# STM32H562xx register map
File version: 1.0
Registers are 32-bit, read-write, reset 0x0 unless marked. A register's access mark holds for its fields unless they carry their own. Offsets are from the block's base; [hi:lo] are bit positions; {n}, {i} and the like mark numbered series.

## VREFBUF
Base 0x44007400
Same registers: VREFBUF_S 0x54007400
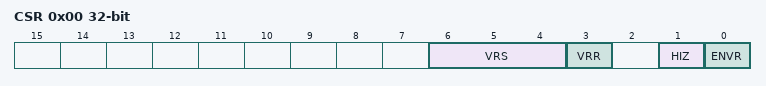
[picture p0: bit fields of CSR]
0x00 CSR — VREFBUF control and status register
  [6:4] VRS — Voltage reference scale
    {v}=SCALE{v} (Voltage reference scale {v} (VREF_OUT{v+1})) (v=0..3)
  [3] VRR — Voltage reference buffer ready
  [1] HIZ — High impedance mode
  [0] ENVR — Voltage reference buffer enable
0x04 CCR — VREFBUF calibration and control register
  [5:0] TRIM — TRIM[5:0] bits (Trimming code)

## PWR — Power Control
Base 0x44020800
Same registers: PWR_S 0x54020800
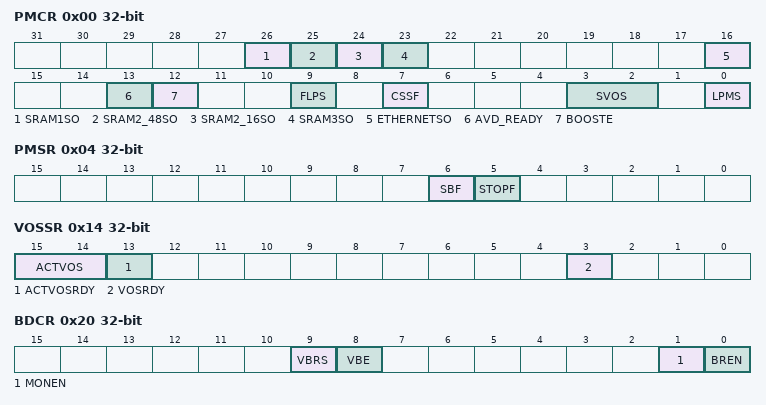
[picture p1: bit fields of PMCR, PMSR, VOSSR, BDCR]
0x00 PMCR — Power mode control register
  [26] SRAM1SO
  [25] SRAM2_48SO
  [24] SRAM2_16SO
  [23] SRAM3SO
  [16] ETHERNETSO
  [13] AVD_READY
  [12] BOOSTE
  [9] FLPS
  [7] CSSF
  [3:2] SVOS
    3=SCALE3 (Select voltage scale 3 when system enters STOP mode); 2=SCALE4 (Select voltage scale 4 when system enters STOP mode); 1=SCALE5 (Select voltage scale 5 when system enters STOP mode)
  [0] LPMS
    0=STOP_MODE (STOP 0 mode); 1=STANDBY_MODE
0x04 PMSR — Power mode status register
  [6] SBF, [5] STOPF
0x10 VOSCR — Voltage scaling control register
  [5:4] VOS
    3=SCALE0 (Voltage scaling range 0); 2=SCALE1 (Voltage scaling range 1); 1=SCALE2 (Voltage scaling range 2); 0=SCALE3 (Voltage scaling range 3)
0x14 VOSSR — Voltage sacling status register
  [15:14] ACTVOS, [13] ACTVOSRDY, [3] VOSRDY
0x20 BDCR — BacKup domain control register
  [9] VBRS
    0=RESISTOR_5K (Charge the battery through a 5 kO resistor); 1=RESISTOR_1_5K (Charge the battery through a 1.5 kO resistor)
  [8] VBE
  [1] MONEN
  [0] BREN
0x24 DBPCR — DBP control register
  [0] DBP
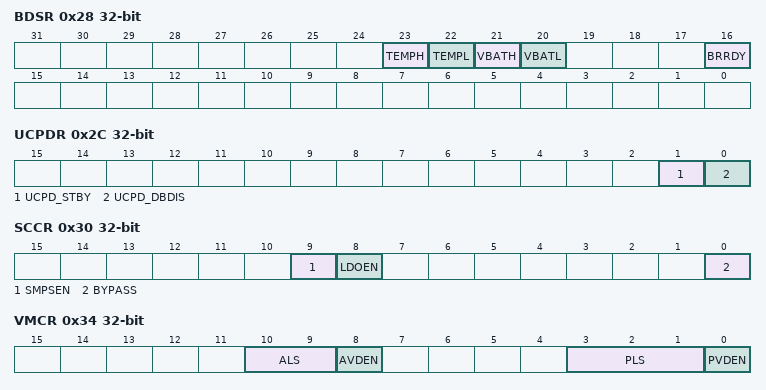
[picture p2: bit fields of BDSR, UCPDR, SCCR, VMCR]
0x28 BDSR — BacKup domain status register
  [23] TEMPH, [22] TEMPL, [21] VBATH, [20] VBATL, [16] BRRDY
0x2C UCPDR — Usb typeC and Power Delivery Register
  [1] UCPD_STBY, [0] UCPD_DBDIS
0x30 SCCR — Supply configuration control register
  [9] SMPSEN, [8] LDOEN, [0] BYPASS
0x34 VMCR — Voltage Monitor Control Register
  [10:9] ALS
    0=AVDLEVEL_0 (Analog Voltage threshold detected by AVD 1.7 V); 1=AVDLEVEL_1 (Analog Voltage threshold detected by AVD 2.1 V); 2=AVDLEVEL_2 (Analog Voltage threshold detected by AVD 2.5 V); 3=AVDLEVEL_3 (Analog Voltage threshold detected by AVD 2.8 V)
  [8] AVDEN
  [3:1] PLS
    0=PVDLEVEL_0 (Voltage threshold detected by PVD 1.95 V); 1=PVDLEVEL_1 (Voltage threshold detected by PVD 2.10 V); 2=PVDLEVEL_2 (Voltage threshold detected by PVD 2.25 V); 3=PVDLEVEL_3 (Voltage threshold detected by PVD 2.40 V); 4=PVDLEVEL_4 (Voltage threshold detected by PVD 2.55 V); 5=PVDLEVEL_5 (Voltage threshold detected by PVD 2.70 V); 6=PVDLEVEL_6 (Voltage threshold detected by PVD 2.85 V); 7=PVDLEVEL_7
  [0] PVDEN
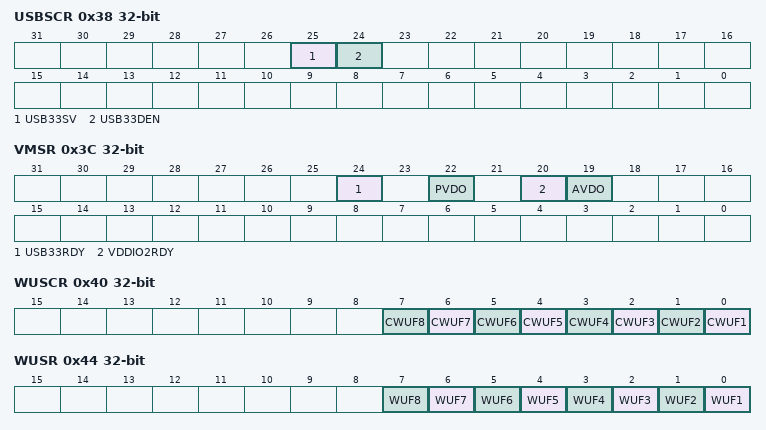
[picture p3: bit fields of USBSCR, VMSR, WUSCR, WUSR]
0x38 USBSCR — USB Supply Control Register
  [25] USB33SV, [24] USB33DEN
0x3C VMSR — Status Register Voltage Monitoring
  [24] USB33RDY, [22] PVDO, [20] VDDIO2RDY, [19] AVDO
0x40 WUSCR — WakeUP status clear register
  [n-1] CWUF{n} (n=1..8)
0x44 WUSR — WakeUP status Register
  [n-1] WUF{n} (n=1..8)
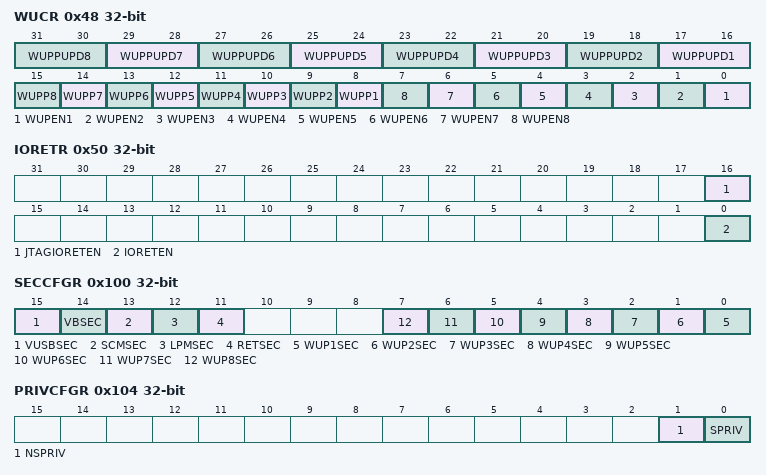
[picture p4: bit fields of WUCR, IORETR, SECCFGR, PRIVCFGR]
0x48 WUCR — WakeUP configuration register
  [2n+15:2n+14] WUPPUPD{n} (n=1..8), [n+7] WUPP{n} (n=1..8), [n-1] WUPEN{n} (n=1..8)
0x50 IORETR — IO RETention Register
  [16] JTAGIORETEN, [0] IORETEN
0x100 SECCFGR — Security configuration register
  [15] VUSBSEC, [14] VBSEC, [13] SCMSEC, [12] LPMSEC, [11] RETSEC, [n-1] WUP{n}SEC (n=1..8)
0x104 PRIVCFGR — Privilege configuration register
  [1] NSPRIV, [0] SPRIV

## EXTI — Asynch Interrupt/Event Controller (EXTI)
Base 0x44022000
Same registers: EXTI_S 0x54022000
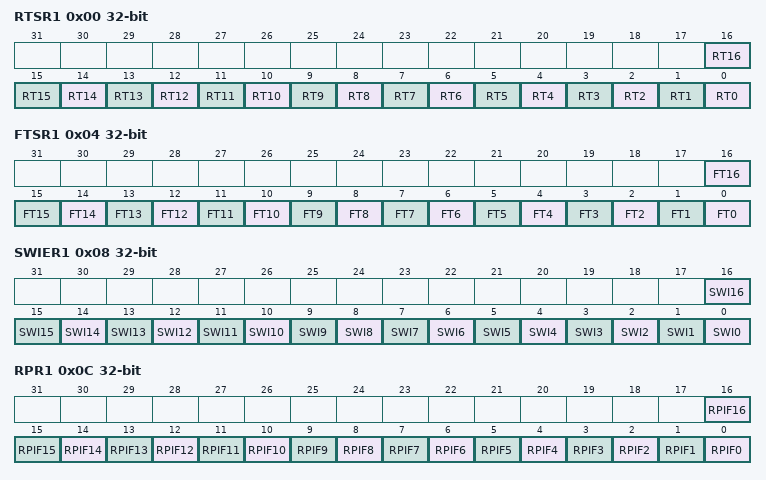
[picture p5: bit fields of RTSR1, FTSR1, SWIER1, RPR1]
0x00 RTSR1 — EXTI Rising Trigger Selection Register 1
  [n] RT{n} (n=0..16) — Rising trigger configuration for input line {n}
0x04 FTSR1 — EXTI Falling Trigger Selection Register 1
  [n] FT{n} (n=0..16) — Falling trigger configuration for input line {n}
0x08 SWIER1 — EXTI Software Interrupt event Register 1
  [n] SWI{n} (n=0..16) — Software Interrupt on line {n}
0x0C RPR1 — EXTI Rising Pending Register 1
  [n] RPIF{n} (n=0..16) — Rising Pending Interrupt Flag on line {n}
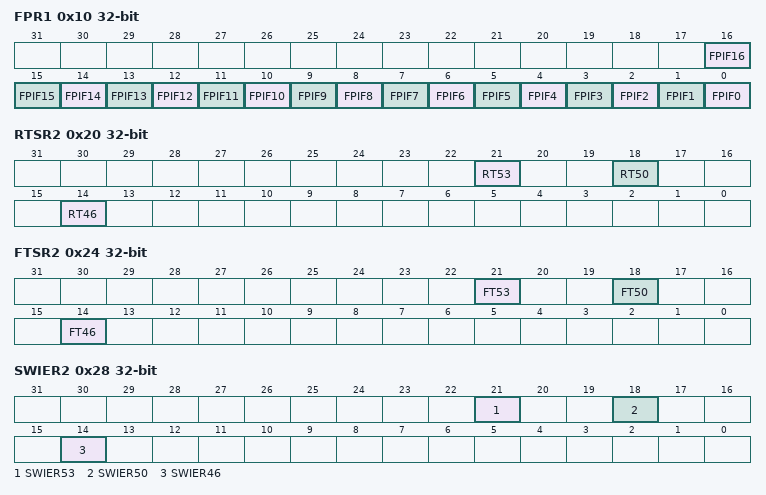
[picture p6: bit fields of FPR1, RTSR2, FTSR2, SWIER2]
0x10 FPR1 — EXTI Falling Pending Register 1
  [n] FPIF{n} (n=0..16) — Falling Pending Interrupt Flag on line {n}
0x14 SECCFGR1 — EXTI Security Configuration Register 1
0x18 PRIVCFGR1 — EXTI Privilege Configuration Register 1
0x20 RTSR2 — EXTI Rising Trigger Selection Register 2
  [21] RT53 — Rising trigger event configuration bit of line 53
  [18] RT50 — Rising trigger event configuration bit of line 50
  [14] RT46 — Rising trigger event configuration bit of line 46
0x24 FTSR2 — EXTI Falling Trigger Selection Register 2
  [21] FT53 — Falling trigger event configuration bit of line 53
  [18] FT50 — Falling trigger event configuration bit of line 50
  [14] FT46 — Falling trigger event configuration bit of line 46
0x28 SWIER2 — EXTI Software Interrupt event Register 2
  [21] SWIER53 — Software Interrupt on line 53
  [18] SWIER50 — Software Interrupt on line 50
  [14] SWIER46 — Software Interrupt on line 46
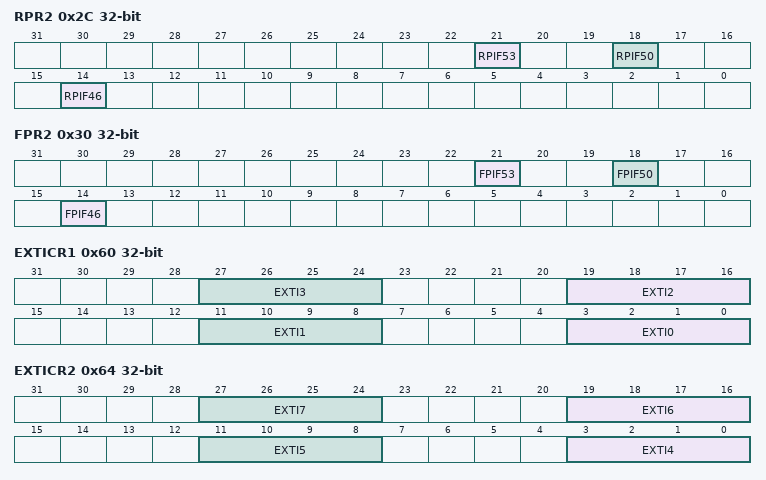
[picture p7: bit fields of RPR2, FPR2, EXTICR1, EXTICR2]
0x2C RPR2 — EXTI Rising Pending Register 2
  [21] RPIF53 — Rising pending edge configuration bit of line 53
  [18] RPIF50 — Rising pending edge configuration bit of line 50
  [14] RPIF46 — Rising pending edge configuration bit of line 46
0x30 FPR2 — EXTI Falling Pending Register 2
  [21] FPIF53 — Rising falling edge configuration bit of line 53
  [18] FPIF50 — Rising falling edge configuration bit of line 50
  [14] FPIF46 — Rising falling edge configuration bit of line 46
0x34 SECCFGR2 — EXTI Security Configuration Register 2
0x38 PRIVCFGR2 — EXTI Privilege Configuration Register 2
0x60 EXTICR1 — EXIT External Interrupt Configuration Register, 0x60 -- 0x6C
  [8n+3:8n] EXTI{n} (n=0..3) — EXTI {n} configuration
0x64 EXTICR2 — EXIT External Interrupt Configuration Register, 0x60 -- 0x6C
  [8n-29:8n-32] EXTI{n} (n=4..7) — EXTI {n} configuration
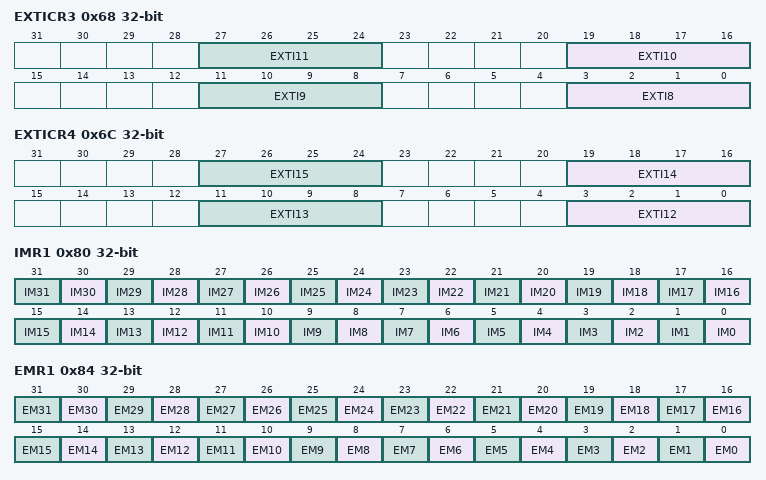
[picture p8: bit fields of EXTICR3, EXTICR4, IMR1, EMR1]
0x68 EXTICR3 — EXIT External Interrupt Configuration Register, 0x60 -- 0x6C
  [8n-61:8n-64] EXTI{n} (n=8..11) — EXTI {n} configuration
0x6C EXTICR4 — EXIT External Interrupt Configuration Register, 0x60 -- 0x6C
  [8n-93:8n-96] EXTI{n} (n=12..15) — EXTI {n} configuration
0x70 LOCKR — EXTI Lock Register
  [0] LOCK — Lock Mask
0x80 IMR1 — EXTI Interrupt Mask Register 1
  [n] IM{n} (n=0..31) — Interrupt Mask on line {n}
0x84 EMR1 — EXTI Event Mask Register 1
  [n] EM{n} (n=0..31) — Event Mask on line {n}
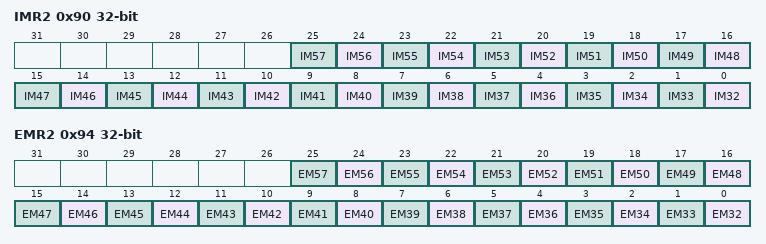
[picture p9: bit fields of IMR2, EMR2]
0x90 IMR2 — EXTI Interrupt Mask Register 2
  [n-32] IM{n} (n=32..57) — Interrupt Mask on line {n}
0x94 EMR2 — EXTI Event Mask Register 2
  [n-32] EM{n} (n=32..57) — Event Mask on line {n}
